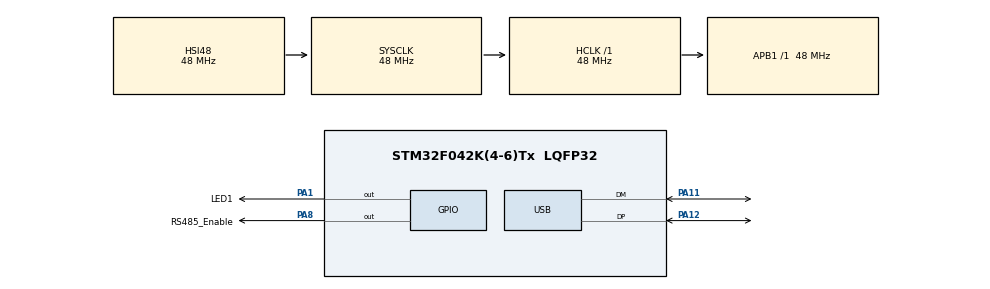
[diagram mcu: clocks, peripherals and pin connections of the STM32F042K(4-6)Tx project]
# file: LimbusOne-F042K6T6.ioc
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Mcu.Family=STM32F0
Mcu.Name=STM32F042K(4-6)Tx
Mcu.Package=LQFP32
NVIC.USB_IRQn=true\:0\:0\:false\:false\:true\:false\:true\:true
PA1.GPIO_Label=LED1
PA1.Signal=GPIO_Output
PA11.Mode=Device
PA11.Signal=USB_DM
PA12.Mode=Device
PA12.Signal=USB_DP
PA13.Mode=Serial_Wire
PA13.Signal=SYS_SWDIO
PA14.Mode=Serial_Wire
PA14.Signal=SYS_SWCLK
PA8.GPIO_Label=RS485_Enable
PA8.Signal=GPIO_Output
ProjectManager.HeapSize=0x80
ProjectManager.StackSize=0x400
ProjectManager.TargetToolchain=STM32CubeIDE
RCC.AHBFreq_Value=48000000
RCC.APB1Freq_Value=48000000
RCC.APB1TimFreq_Value=48000000
RCC.HCLKFreq_Value=48000000
RCC.SYSCLKFreq_VALUE=48000000
RCC.SYSCLKSource=RCC_SYSCLKSOURCE_HSI48
USB_DEVICE.CLASS_NAME_FS=CDC
USB_DEVICE.PRODUCT_STRING_CDC_FS=LuggisPurpleThing
USB_DEVICE.VirtualMode=Cdc
USB_DEVICE.VirtualModeFS=Cdc_FS
VP_USB_DEVICE_VS_USB_DEVICE_CDC_FS.Mode=CDC_FS
board=custom

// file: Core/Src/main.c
/* USER CODE BEGIN Header */
/**
  ******************************************************************************
  * @file           : main.c
  * @brief          : Main program body
  ******************************************************************************
  * @attention
  *
  * Copyright (c) 2024 STMicroelectronics.
  * All rights reserved.
  *
  * This software is licensed under terms that can be found in the LICENSE file
  * in the root directory of this software component.
  * If no LICENSE file comes with this software, it is provided AS-IS.
  *
  ******************************************************************************
  */
/* USER CODE END Header */
#include "main.h"
#include "usb_device.h"

/* USER CODE BEGIN Includes */
#include "usbd_cdc_if.h"
/* USER CODE END Includes */

void SystemClock_Config(void);
static void MX_GPIO_Init(void);

int main(void)
{

  /* MCU Configuration--------------------------------------------------------*/

  /* Reset of all peripherals, Initializes the Flash interface and the Systick. */
  HAL_Init();

  /* Configure the system clock */
  SystemClock_Config();

  /* Initialize all configured peripherals */
  MX_GPIO_Init();
  //MX_USB_DEVICE_Init();
  /* USER CODE BEGIN 2 */

  char buffer[] = "I like Pink!\r\n";

  /* USER CODE END 2 */

  /* Infinite loop */
  while (1)
  {

    /* USER CODE BEGIN 3 */
	  //CDC_Transmit_FS((uint8_t*)buffer, strlen(buffer));
	  HAL_GPIO_TogglePin(LED1_GPIO_Port, LED1_Pin);
	  HAL_Delay(500);
  }
  /* USER CODE END 3 */
}

void SystemClock_Config(void)
{
  RCC_OscInitTypeDef RCC_OscInitStruct = {0};
  RCC_ClkInitTypeDef RCC_ClkInitStruct = {0};
  RCC_PeriphCLKInitTypeDef PeriphClkInit = {0};

  /** Initializes the RCC Oscillators according to the specified parameters
  * in the RCC_OscInitTypeDef structure.
  */
  RCC_OscInitStruct.OscillatorType = RCC_OSCILLATORTYPE_HSI48;
  RCC_OscInitStruct.HSI48State = RCC_HSI48_ON;
  RCC_OscInitStruct.PLL.PLLState = RCC_PLL_NONE;
  if (HAL_RCC_OscConfig(&RCC_OscInitStruct) != HAL_OK)
  {
    Error_Handler();
  }

  /** Initializes the CPU, AHB and APB buses clocks
  */
  RCC_ClkInitStruct.ClockType = RCC_CLOCKTYPE_HCLK|RCC_CLOCKTYPE_SYSCLK
                              |RCC_CLOCKTYPE_PCLK1;
  RCC_ClkInitStruct.SYSCLKSource = RCC_SYSCLKSOURCE_HSI48;
  RCC_ClkInitStruct.AHBCLKDivider = RCC_SYSCLK_DIV1;
  RCC_ClkInitStruct.APB1CLKDivider = RCC_HCLK_DIV1;

  if (HAL_RCC_ClockConfig(&RCC_ClkInitStruct, FLASH_LATENCY_1) != HAL_OK)
  {
    Error_Handler();
  }
  PeriphClkInit.PeriphClockSelection = RCC_PERIPHCLK_USB;
  PeriphClkInit.UsbClockSelection = RCC_USBCLKSOURCE_HSI48;

  if (HAL_RCCEx_PeriphCLKConfig(&PeriphClkInit) != HAL_OK)
  {
    Error_Handler();
  }
}

static void MX_GPIO_Init(void)
{
  GPIO_InitTypeDef GPIO_InitStruct = {0};

  /* GPIO Ports Clock Enable */
  __HAL_RCC_GPIOA_CLK_ENABLE();

  /*Configure GPIO pin Output Level */
  HAL_GPIO_WritePin(GPIOA, LED1_Pin|RS485_Enable_Pin, GPIO_PIN_RESET);

  /*Configure GPIO pins : LED1_Pin RS485_Enable_Pin */
  GPIO_InitStruct.Pin = LED1_Pin|RS485_Enable_Pin;
  GPIO_InitStruct.Mode = GPIO_MODE_OUTPUT_PP;
  GPIO_InitStruct.Pull = GPIO_NOPULL;
  GPIO_InitStruct.Speed = GPIO_SPEED_FREQ_LOW;
  HAL_GPIO_Init(GPIOA, &GPIO_InitStruct);

}

void Error_Handler(void)
{
  __disable_irq();
  while (1)
  {
  }
}
